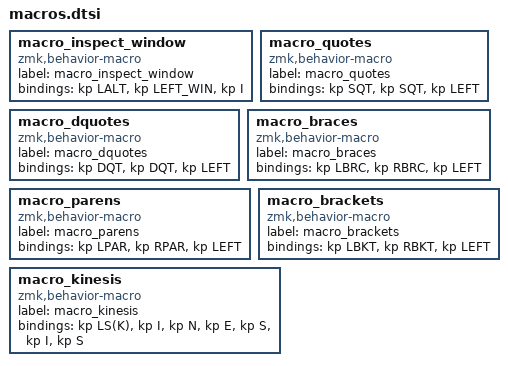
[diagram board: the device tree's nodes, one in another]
macro_inspect_window: macro_inspect_window{
compatible = "zmk,behavior-macro";
label = "macro_inspect_window";
#binding-cells = <0>;
bindings = <&kp LALT>, <&kp LEFT_WIN>, <&kp I>;
};
macro_quotes: macro_quotes{
compatible = "zmk,behavior-macro";
label = "macro_quotes";
#binding-cells = <0>;
bindings = <&kp SQT>, <&kp SQT>, <&kp LEFT>;
};
macro_dquotes: macro_dquotes{
compatible = "zmk,behavior-macro";
label = "macro_dquotes";
#binding-cells = <0>;
bindings = <&kp DQT>, <&kp DQT>, <&kp LEFT>;
};
macro_braces: macro_braces{
compatible = "zmk,behavior-macro";
label = "macro_braces";
#binding-cells = <0>;
bindings = <&kp LBRC>, <&kp RBRC>, <&kp LEFT>;
};
macro_parens: macro_parens{
compatible = "zmk,behavior-macro";
label = "macro_parens";
#binding-cells = <0>;
bindings = <&kp LPAR>, <&kp RPAR>, <&kp LEFT>;
};
macro_brackets: macro_brackets{
compatible = "zmk,behavior-macro";
label = "macro_brackets";
#binding-cells = <0>;
bindings = <&kp LBKT>, <&kp RBKT>, <&kp LEFT>;
};
macro_kinesis: macro_kinesis{
compatible = "zmk,behavior-macro";
label = "macro_kinesis";
#binding-cells = <0>;
bindings = <&kp LS(K)>, <&kp I>, <&kp N>, <&kp E>, <&kp S>, <&kp I>, <&kp S>;
};
// macro_layer_swap_with_modifier macro definition
// macro_layer_swap_with_modifier: macro_layer_swap_with_modifier {
//     compatible = "zmk,behavior-macro-two-param";
//     label = "mlswp";
//     #binding-cells = <2>;
//     bindings
//         = <&macro_param_1to1>
//         , <&macro_press &mo MACRO_PLACEHOLDER>
//         , <&macro_param_2to1>
//         , <&macro_press &kp MACRO_PLACEHOLDER>
//         , <&macro_pause_for_release>
//         , <&macro_param_2to1>
//         , <&macro_release &kp MACRO_PLACEHOLDER>
//         , <&macro_param_1to1>
//         , <&macro_release &mo MACRO_PLACEHOLDER>
//         ;
// };
// there's a problem with this, I think we need to sub out the MACRO_PLACEHOLDER
// lm: lm {
//     compatible = "zmk,behavior-macro-two-param";
//     wait-ms = <0>;
//     tap-ms = <0>;
//     #binding-cells = <2>;
//     bindings
//         = <&macro_param_1to1>
//         , <&macro_press &mo MACRO_PLACEHOLDER>
//         , <&macro_param_2to1>
//         , <&macro_press &kp MACRO_PLACEHOLDER>
//         , <&macro_pause_for_release>
//         , <&macro_param_2to1>
//         , <&macro_release &kp MACRO_PLACEHOLDER>
//         , <&macro_param_1to1>
//         , <&macro_release &mo MACRO_PLACEHOLDER>
//         ;
// };
